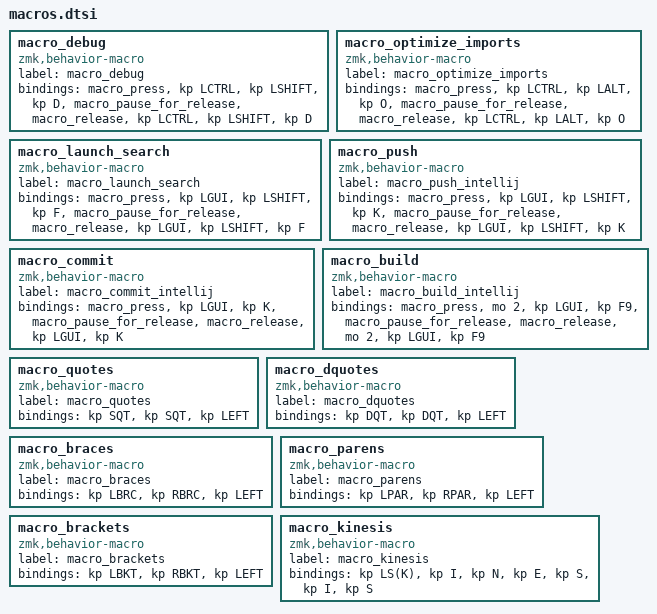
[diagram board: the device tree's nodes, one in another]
macro_debug: macro_debug {
label = "macro_debug";
compatible = "zmk,behavior-macro";
#binding-cells = <0>;
bindings = <&macro_press &kp LCTRL &kp LSHIFT &kp D>
 ,<&macro_pause_for_release>
 ,<&macro_release &kp LCTRL &kp LSHIFT &kp D>;
};
macro_optimize_imports: macro_optimize_imports {
label = "macro_optimize_imports";
compatible = "zmk,behavior-macro";
#binding-cells = <0>;
bindings = <&macro_press &kp LCTRL &kp LALT &kp O>
 ,<&macro_pause_for_release>
 ,<&macro_release &kp LCTRL &kp LALT &kp O>;
};
macro_launch_search: macro_launch_search {
label = "macro_launch_search";
compatible = "zmk,behavior-macro";
#binding-cells = <0>;
bindings = <&macro_press &kp LGUI &kp LSHIFT &kp F>
 ,<&macro_pause_for_release>
 ,<&macro_release &kp LGUI &kp LSHIFT &kp F>;
};
macro_push: macro_push {
label = "macro_push_intellij";
compatible = "zmk,behavior-macro";
#binding-cells = <0>;
bindings = <&macro_press &kp LGUI &kp LSHIFT &kp K>
 ,<&macro_pause_for_release>
 ,<&macro_release &kp LGUI &kp LSHIFT &kp K>;
};
macro_commit: macro_commit {
label = "macro_commit_intellij";
compatible = "zmk,behavior-macro";
#binding-cells = <0>;
bindings = <&macro_press &kp LGUI &kp K>
  ,<&macro_pause_for_release>
  ,<&macro_release &kp LGUI &kp K>;
};
macro_build: macro_build {
label = "macro_build_intellij";
compatible = "zmk,behavior-macro";
#binding-cells = <0>;
bindings = <&macro_press &mo 2 &kp LGUI &kp F9>
    ,<&macro_pause_for_release>
    ,<&macro_release &mo 2 &kp LGUI &kp F9>;
};
macro_quotes: macro_quotes{
compatible = "zmk,behavior-macro";
label = "macro_quotes";
#binding-cells = <0>;
bindings = <&kp SQT>, <&kp SQT>, <&kp LEFT>;
};
macro_dquotes: macro_dquotes{
compatible = "zmk,behavior-macro";
label = "macro_dquotes";
#binding-cells = <0>;
bindings = <&kp DQT>, <&kp DQT>, <&kp LEFT>;
};
macro_braces: macro_braces{
compatible = "zmk,behavior-macro";
label = "macro_braces";
#binding-cells = <0>;
bindings = <&kp LBRC>, <&kp RBRC>, <&kp LEFT>;
};
macro_parens: macro_parens{
compatible = "zmk,behavior-macro";
label = "macro_parens";
#binding-cells = <0>;
bindings = <&kp LPAR>, <&kp RPAR>, <&kp LEFT>;
};
macro_brackets: macro_brackets{
compatible = "zmk,behavior-macro";
label = "macro_brackets";
#binding-cells = <0>;
bindings = <&kp LBKT>, <&kp RBKT>, <&kp LEFT>;
};
macro_kinesis: macro_kinesis{
compatible = "zmk,behavior-macro";
label = "macro_kinesis";
#binding-cells = <0>;
bindings = <&kp LS(K)>, <&kp I>, <&kp N>, <&kp E>, <&kp S>, <&kp I>, <&kp S>;
};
